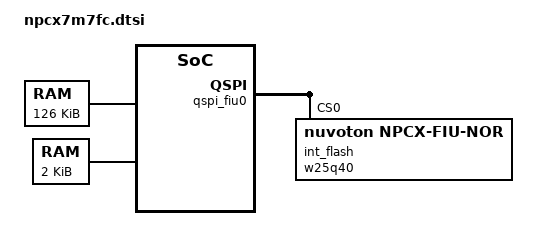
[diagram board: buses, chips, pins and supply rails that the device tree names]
/*
 * Copyright (c) 2021 Nuvoton Technology Corporation.
 *
 * SPDX-License-Identifier: Apache-2.0
 */

#include <mem.h>
#include "npcx/npcx7.dtsi"

/ {
	flash0: flash@10070000 {
		/*
		 * Reallocate the last 64 KB of code RAM for use as data RAM
		 * because the internal flash size is 512 KB.
		 */
		reg = <0x10070000 DT_SIZE_K(256)>;
	};

	flash1: flash@64000000 {
		reg = <0x64000000 DT_SIZE_K(512)>;
	};

	sram0: memory@200b0000 {
		compatible = "mmio-sram";
		reg = <0x200B0000 DT_SIZE_K(126)>;
	};

	/* RAM space used by Booter */
	bootloader_ram: memory@200cf800 {
		compatible = "mmio-sram";
		reg = <0x200CF800 DT_SIZE_K(2)>;
	};

	soc-id {
		device-id = <0x20>;
	};
};

&qspi_fiu0 {
	status = "okay";

	int_flash: w25q40@0 {
		compatible ="nuvoton,npcx-fiu-nor";
		size = <DT_SIZE_K(512 * 8)>;
		reg = <0>;
		status = "okay";

		/* quad spi bus configuration of nor flash device */
		qspi-flags = <NPCX_QSPI_SW_CS1>;
		mapped-addr = <0x64000000>;
		pinctrl-0 = <&int_flash_sl>;
		pinctrl-names = "default";
	};
};
